# MLB register map
Vendor: Texas Instruments
Peripheral module from a debugger description file (folder omap36xx).
Registers are 32-bit, read-only, reset 0x0 unless marked. A register's access mark holds for its fields unless they carry their own. Offsets are as the file gives them; lines under a group give offsets from that group; [hi:lo] are bit positions; {n}, {i} and the like mark numbered series; 'fields as' and 'values as' point back to an identical list; <NAME> marks a mode.

## MLB
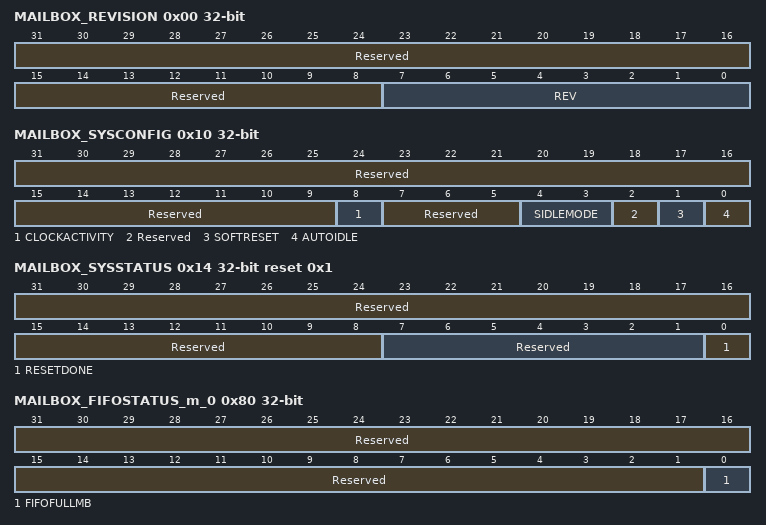
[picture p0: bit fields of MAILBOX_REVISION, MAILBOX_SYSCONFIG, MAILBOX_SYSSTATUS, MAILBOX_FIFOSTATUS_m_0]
0x00 MAILBOX_REVISION (reset mask 0xFFFFFF00) — This register contains the IP revision code
  [31:8] Reserved — Reads returns 0
  [7:0] REV — IP revision[7:4] Major revision[3:0] Minor revisionExamples: 0x10 for 1.0, 0x21 for 2.1
0x10 MAILBOX_SYSCONFIG access per field — This register controls the various parameters of the L4-Core interface
  [31:9] Reserved rw — Write 0's for future compatibilityRead returns 0
  [8] CLOCKACTIVITY ro — Clock activity during wake up mode periodClock can always be switched off and read returns 0
  [7:5] Reserved rw — Write 0's for future compatibilityRead returns 0
  [4:3] SIDLEMODE rw
    0=Force-idle. An idle request is acknowledged unconditionally; 1=No-idle. An idle request is never acknowledged; 2=Smart-idle. Acknowledgement to an idle request is given based on the internal activity of the module based on the internal activity of the module; 3=Reserved. Do not use.
  [2] Reserved rw — Write 0's for future compatibility Read returns 0
  [1] SOFTRESET rw — Software reset. This bit is automatically reset by the hardware. During reads, it always return 0
    0=Normal mode; 1=The module is reset
  [0] AUTOIDLE rw — Internal interface clock gating strategy
    0=Interface clock is free-running; 1=Automatic interface clock gating strategy is applied, based on the L4-Core interface activity
0x14 MAILBOX_SYSSTATUS reset 0x1 — This register provides status information about the module, excluding the interrupt status information
  [31:8] Reserved — Read returns 0
  [7:1] Reserved — Read returns 0
  [0] RESETDONE — Internal reset monitoring
    0=RESETDONE_0_r (Internal module reset in on-going); 1=RESETDONE_1_r (Reset completed)
0x40 MAILBOX_MESSAGE_m_0 rw — The message register stores the next to be read message of the mailbox X
  [31:0] MESSAGEVALUEMB — Message in Mailbox
0x44 MAILBOX_MESSAGE_m_1 rw — The message register stores the next to be read message of the mailbox X
  [31:0] MESSAGEVALUEMB — Message in Mailbox
0x80 MAILBOX_FIFOSTATUS_m_0 — The FIFO status register has the status related to the mailbox internal FIFO
  [31:1] Reserved — Read returns 0
  [0] FIFOFULLMB — Full flag for Mailbox
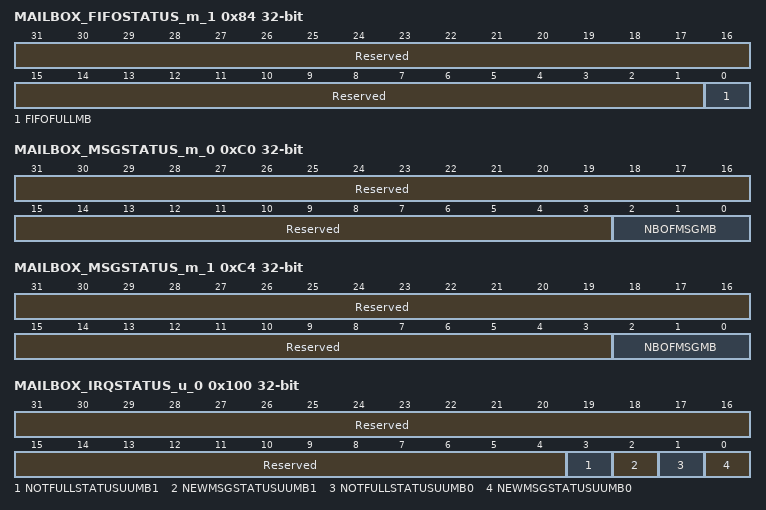
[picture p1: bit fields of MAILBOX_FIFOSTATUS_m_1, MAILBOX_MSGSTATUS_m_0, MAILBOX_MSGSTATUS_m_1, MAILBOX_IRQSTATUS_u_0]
0x84 MAILBOX_FIFOSTATUS_m_1 — The FIFO status register has the status related to the mailbox internal FIFO
  fields as MAILBOX_FIFOSTATUS_m_0
0xC0 MAILBOX_MSGSTATUS_m_0 — The message status register has the status of the messages in the mailbox
  [31:3] Reserved — Read returns 0
  [2:0] NBOFMSGMB — Number of Messages in MailboxNote: Limited to four messages per mailbox.
0xC4 MAILBOX_MSGSTATUS_m_1 — The message status register has the status of the messages in the mailbox
  fields as MAILBOX_MSGSTATUS_m_0
0x100 MAILBOX_IRQSTATUS_u_0 rw — The interrupt status register has the status for each event that may be responsible for the generation of an interrupt to the corresponding user - write 1 to a given bit resets this bit
  [31:4] Reserved — Write 0s for future compatibility Read returns 0
  [3] NOTFULLSTATUSUUMB1 — NotFull Status bit for User u, Mailbox 1
  [2] NEWMSGSTATUSUUMB1 — NewMessage Status bit for User u, Mailbox 1
  [1] NOTFULLSTATUSUUMB0 — NotFull Status bit for User u, Mailbox 0
  [0] NEWMSGSTATUSUUMB0 — NewMessage Status bit for User u, Mailbox 0
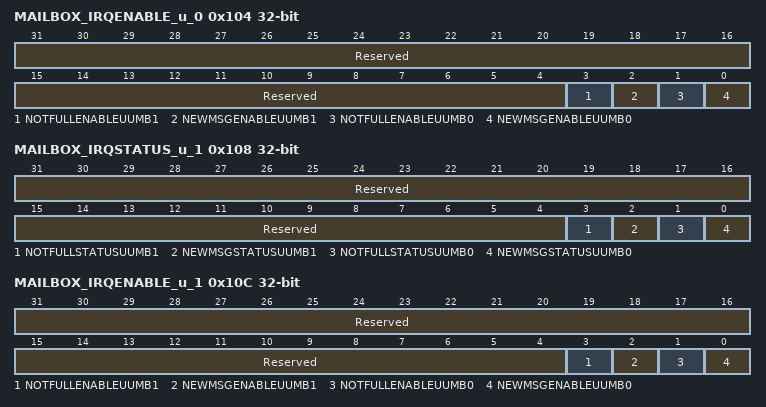
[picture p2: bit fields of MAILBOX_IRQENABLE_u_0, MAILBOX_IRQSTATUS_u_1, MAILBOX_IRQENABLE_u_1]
0x104 MAILBOX_IRQENABLE_u_0 rw — The interrupt enable register enables to mask/unmask the module internal source of interrupt to the corresponding user
  [31:4] Reserved — Write 0s for future compatibility. Read returns 0
  [3] NOTFULLENABLEUUMB1 — NotFull Enable bit for User u, Mailbox 1
  [2] NEWMSGENABLEUUMB1 — NewMessage Enable bit for User u, Mailbox 1
  [1] NOTFULLENABLEUUMB0 — NotFull Enable bit for User u, Mailbox 0
  [0] NEWMSGENABLEUUMB0 — NewMessage Enable bit for User u, Mailbox 0
0x108 MAILBOX_IRQSTATUS_u_1 rw — The interrupt status register has the status for each event that may be responsible for the generation of an interrupt to the corresponding user - write 1 to a given bit resets this bit
  fields as MAILBOX_IRQSTATUS_u_0
0x10C MAILBOX_IRQENABLE_u_1 rw — The interrupt enable register enables to mask/unmask the module internal source of interrupt to the corresponding user
  fields as MAILBOX_IRQENABLE_u_0
